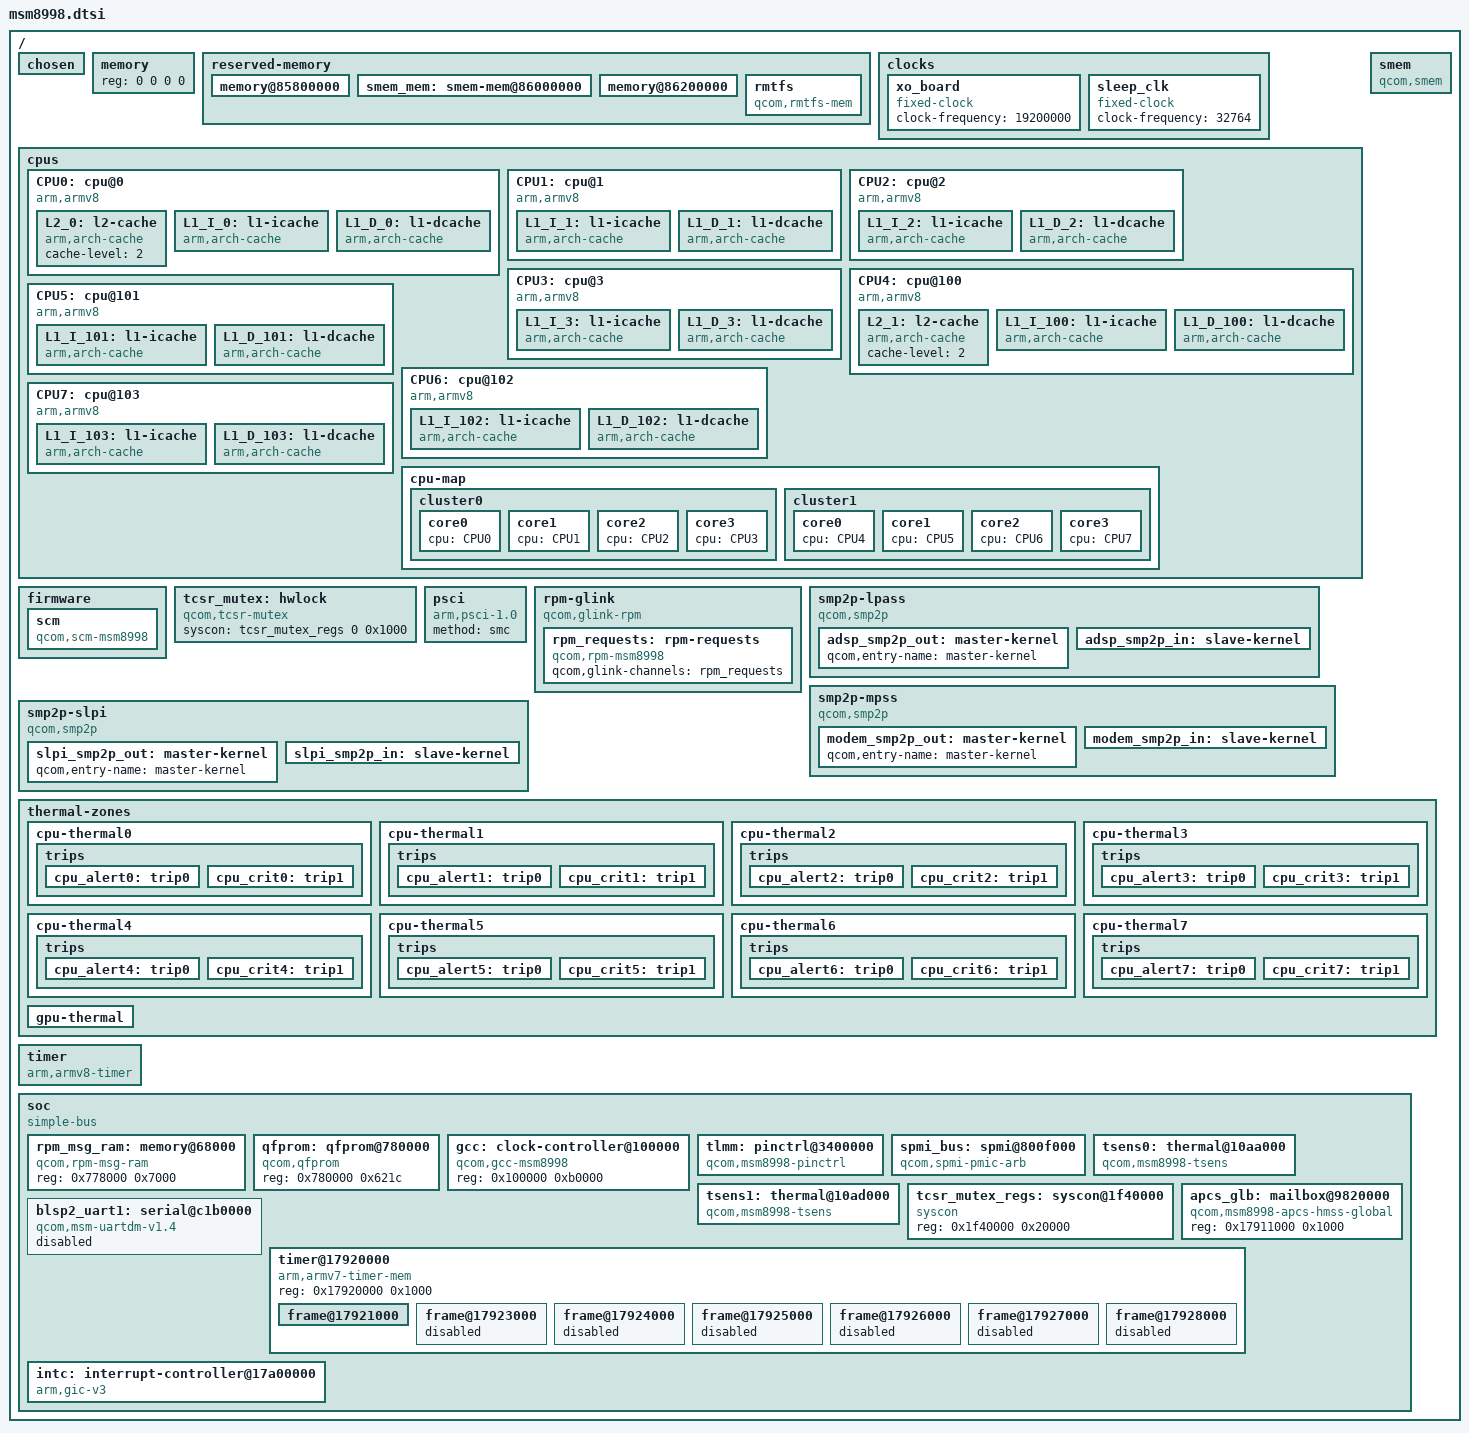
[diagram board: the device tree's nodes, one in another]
// SPDX-License-Identifier: GPL-2.0
/* Copyright (c) 2016, The Linux Foundation. All rights reserved. */

#include <dt-bindings/interrupt-controller/arm-gic.h>
#include <dt-bindings/clock/qcom,gcc-msm8998.h>

/ {
	interrupt-parent = <&intc>;

	qcom,msm-id = <292 0x0>;

	#address-cells = <2>;
	#size-cells = <2>;

	chosen { };

	memory {
		device_type = "memory";
		/* We expect the bootloader to fill in the reg */
		reg = <0 0 0 0>;
	};

	reserved-memory {
		#address-cells = <2>;
		#size-cells = <2>;
		ranges;

		memory@85800000 {
			reg = <0x0 0x85800000 0x0 0x800000>;
			no-map;
		};

		smem_mem: smem-mem@86000000 {
			reg = <0x0 0x86000000 0x0 0x200000>;
			no-map;
		};

		memory@86200000 {
			reg = <0x0 0x86200000 0x0 0x2600000>;
			no-map;
		};

		rmtfs {
			compatible = "qcom,rmtfs-mem";

			size = <0x0 0x200000>;
			alloc-ranges = <0x0 0xa0000000 0x0 0x2000000>;
			no-map;

			qcom,client-id = <1>;
			qcom,vmid = <15>;
		};
	};

	clocks {
		xo_board {
			compatible = "fixed-clock";
			#clock-cells = <0>;
			clock-frequency = <19200000>;
		};

		sleep_clk {
			compatible = "fixed-clock";
			#clock-cells = <0>;
			clock-frequency = <32764>;
		};
	};

	cpus {
		#address-cells = <2>;
		#size-cells = <0>;

		CPU0: cpu@0 {
			device_type = "cpu";
			compatible = "arm,armv8";
			reg = <0x0 0x0>;
			enable-method = "psci";
			efficiency = <1024>;
			next-level-cache = <&L2_0>;
			L2_0: l2-cache {
				compatible = "arm,arch-cache";
				cache-level = <2>;
			};
			L1_I_0: l1-icache {
				compatible = "arm,arch-cache";
			};
			L1_D_0: l1-dcache {
				compatible = "arm,arch-cache";
			};
		};

		CPU1: cpu@1 {
			device_type = "cpu";
			compatible = "arm,armv8";
			reg = <0x0 0x1>;
			enable-method = "psci";
			efficiency = <1024>;
			next-level-cache = <&L2_0>;
			L1_I_1: l1-icache {
				compatible = "arm,arch-cache";
			};
			L1_D_1: l1-dcache {
				compatible = "arm,arch-cache";
			};
		};

		CPU2: cpu@2 {
			device_type = "cpu";
			compatible = "arm,armv8";
			reg = <0x0 0x2>;
			enable-method = "psci";
			efficiency = <1024>;
			next-level-cache = <&L2_0>;
			L1_I_2: l1-icache {
				compatible = "arm,arch-cache";
			};
			L1_D_2: l1-dcache {
				compatible = "arm,arch-cache";
			};
		};

		CPU3: cpu@3 {
			device_type = "cpu";
			compatible = "arm,armv8";
			reg = <0x0 0x3>;
			enable-method = "psci";
			efficiency = <1024>;
			next-level-cache = <&L2_0>;
			L1_I_3: l1-icache {
				compatible = "arm,arch-cache";
			};
			L1_D_3: l1-dcache {
				compatible = "arm,arch-cache";
			};
		};

		CPU4: cpu@100 {
			device_type = "cpu";
			compatible = "arm,armv8";
			reg = <0x0 0x100>;
			enable-method = "psci";
			efficiency = <1536>;
			next-level-cache = <&L2_1>;
			L2_1: l2-cache {
				compatible = "arm,arch-cache";
				cache-level = <2>;
			};
			L1_I_100: l1-icache {
				compatible = "arm,arch-cache";
			};
			L1_D_100: l1-dcache {
				compatible = "arm,arch-cache";
			};
		};

		CPU5: cpu@101 {
			device_type = "cpu";
			compatible = "arm,armv8";
			reg = <0x0 0x101>;
			enable-method = "psci";
			efficiency = <1536>;
			next-level-cache = <&L2_1>;
			L1_I_101: l1-icache {
				compatible = "arm,arch-cache";
			};
			L1_D_101: l1-dcache {
				compatible = "arm,arch-cache";
			};
		};

		CPU6: cpu@102 {
			device_type = "cpu";
			compatible = "arm,armv8";
			reg = <0x0 0x102>;
			enable-method = "psci";
			efficiency = <1536>;
			next-level-cache = <&L2_1>;
			L1_I_102: l1-icache {
				compatible = "arm,arch-cache";
			};
			L1_D_102: l1-dcache {
				compatible = "arm,arch-cache";
			};
		};

		CPU7: cpu@103 {
			device_type = "cpu";
			compatible = "arm,armv8";
			reg = <0x0 0x103>;
			enable-method = "psci";
			efficiency = <1536>;
			next-level-cache = <&L2_1>;
			L1_I_103: l1-icache {
				compatible = "arm,arch-cache";
			};
			L1_D_103: l1-dcache {
				compatible = "arm,arch-cache";
			};
		};

		cpu-map {
			cluster0 {
				core0 {
					cpu = <&CPU0>;
				};

				core1 {
					cpu = <&CPU1>;
				};

				core2 {
					cpu = <&CPU2>;
				};

				core3 {
					cpu = <&CPU3>;
				};
			};

			cluster1 {
				core0 {
					cpu = <&CPU4>;
				};

				core1 {
					cpu = <&CPU5>;
				};

				core2 {
					cpu = <&CPU6>;
				};

				core3 {
					cpu = <&CPU7>;
				};
			};
		};
	};

	firmware {
		scm {
			compatible = "qcom,scm-msm8998";
		};
	};

	tcsr_mutex: hwlock {
		compatible = "qcom,tcsr-mutex";
		syscon = <&tcsr_mutex_regs 0 0x1000>;
		#hwlock-cells = <1>;
	};

	psci {
		compatible = "arm,psci-1.0";
		method = "smc";
	};

	rpm-glink {
		compatible = "qcom,glink-rpm";

		interrupts = <GIC_SPI 168 IRQ_TYPE_EDGE_RISING>;
		qcom,rpm-msg-ram = <&rpm_msg_ram>;
		mboxes = <&apcs_glb 0>;

		rpm_requests: rpm-requests {
			compatible = "qcom,rpm-msm8998";
			qcom,glink-channels = "rpm_requests";
		};
	};

	smem {
		compatible = "qcom,smem";
		memory-region = <&smem_mem>;
		hwlocks = <&tcsr_mutex 3>;
	};

	smp2p-lpass {
		compatible = "qcom,smp2p";
		qcom,smem = <443>, <429>;

		interrupts = <GIC_SPI 158 IRQ_TYPE_EDGE_RISING>;

		mboxes = <&apcs_glb 10>;

		qcom,local-pid = <0>;
		qcom,remote-pid = <2>;

		adsp_smp2p_out: master-kernel {
			qcom,entry-name = "master-kernel";
			#qcom,smem-state-cells = <1>;
		};

		adsp_smp2p_in: slave-kernel {
			qcom,entry-name = "slave-kernel";

			interrupt-controller;
			#interrupt-cells = <2>;
		};
	};

	smp2p-mpss {
		compatible = "qcom,smp2p";
		qcom,smem = <435>, <428>;
		interrupts = <GIC_SPI 451 IRQ_TYPE_EDGE_RISING>;
		mboxes = <&apcs_glb 14>;
		qcom,local-pid = <0>;
		qcom,remote-pid = <1>;

		modem_smp2p_out: master-kernel {
			qcom,entry-name = "master-kernel";
			#qcom,smem-state-cells = <1>;
		};

		modem_smp2p_in: slave-kernel {
			qcom,entry-name = "slave-kernel";
			interrupt-controller;
			#interrupt-cells = <2>;
		};
	};

	smp2p-slpi {
		compatible = "qcom,smp2p";
		qcom,smem = <481>, <430>;
		interrupts = <GIC_SPI 178 IRQ_TYPE_EDGE_RISING>;
		mboxes = <&apcs_glb 26>;
		qcom,local-pid = <0>;
		qcom,remote-pid = <3>;

		slpi_smp2p_out: master-kernel {
			qcom,entry-name = "master-kernel";
			#qcom,smem-state-cells = <1>;
		};

		slpi_smp2p_in: slave-kernel {
			qcom,entry-name = "slave-kernel";
			interrupt-controller;
			#interrupt-cells = <2>;
		};
	};

	thermal-zones {
		cpu-thermal0 {
			polling-delay-passive = <250>;
			polling-delay = <1000>;

			thermal-sensors = <&tsens0 6>;

			trips {
				cpu_alert0: trip0 {
					temperature = <75000>;
					hysteresis = <2000>;
					type = "passive";
				};

				cpu_crit0: trip1 {
					temperature = <110000>;
					hysteresis = <2000>;
					type = "critical";
				};
			};
		};

		cpu-thermal1 {
			polling-delay-passive = <250>;
			polling-delay = <1000>;

			thermal-sensors = <&tsens0 7>;

			trips {
				cpu_alert1: trip0 {
					temperature = <75000>;
					hysteresis = <2000>;
					type = "passive";
				};

				cpu_crit1: trip1 {
					temperature = <110000>;
					hysteresis = <2000>;
					type = "critical";
				};
			};
		};

		cpu-thermal2 {
			polling-delay-passive = <250>;
			polling-delay = <1000>;

			thermal-sensors = <&tsens0 8>;

			trips {
				cpu_alert2: trip0 {
					temperature = <75000>;
					hysteresis = <2000>;
					type = "passive";
				};

				cpu_crit2: trip1 {
					temperature = <110000>;
					hysteresis = <2000>;
					type = "critical";
				};
			};
		};

		cpu-thermal3 {
			polling-delay-passive = <250>;
			polling-delay = <1000>;

			thermal-sensors = <&tsens0 9>;

			trips {
				cpu_alert3: trip0 {
					temperature = <75000>;
					hysteresis = <2000>;
					type = "passive";
				};

				cpu_crit3: trip1 {
					temperature = <110000>;
					hysteresis = <2000>;
					type = "critical";
				};
			};
		};

		cpu-thermal4 {
			polling-delay-passive = <250>;
			polling-delay = <1000>;

			thermal-sensors = <&tsens0 10>;

			trips {
				cpu_alert4: trip0 {
					temperature = <75000>;
					hysteresis = <2000>;
					type = "passive";
				};

				cpu_crit4: trip1 {
					temperature = <110000>;
					hysteresis = <2000>;
					type = "critical";
				};
			};
		};

		cpu-thermal5 {
			polling-delay-passive = <250>;
			polling-delay = <1000>;

			thermal-sensors = <&tsens0 11>;

			trips {
				cpu_alert5: trip0 {
					temperature = <75000>;
					hysteresis = <2000>;
					type = "passive";
				};

				cpu_crit5: trip1 {
					temperature = <110000>;
					hysteresis = <2000>;
					type = "critical";
				};
			};
		};

		cpu-thermal6 {
			polling-delay-passive = <250>;
			polling-delay = <1000>;

			thermal-sensors = <&tsens1 0>;

			trips {
				cpu_alert6: trip0 {
					temperature = <75000>;
					hysteresis = <2000>;
					type = "passive";
				};

				cpu_crit6: trip1 {
					temperature = <110000>;
					hysteresis = <2000>;
					type = "critical";
				};
			};
		};

		cpu-thermal7 {
			polling-delay-passive = <250>;
			polling-delay = <1000>;

			thermal-sensors = <&tsens1 1>;

			trips {
				cpu_alert7: trip0 {
					temperature = <75000>;
					hysteresis = <2000>;
					type = "passive";
				};

				cpu_crit7: trip1 {
					temperature = <110000>;
					hysteresis = <2000>;
					type = "critical";
				};
			};
		};

		gpu-thermal {
			polling-delay-passive = <250>;
			polling-delay = <1000>;

			thermal-sensors = <&tsens1 3>;
		};
	};

	timer {
		compatible = "arm,armv8-timer";
		interrupts = <GIC_PPI 1 IRQ_TYPE_LEVEL_LOW>,
			     <GIC_PPI 2 IRQ_TYPE_LEVEL_LOW>,
			     <GIC_PPI 3 IRQ_TYPE_LEVEL_LOW>,
			     <GIC_PPI 0 IRQ_TYPE_LEVEL_LOW>;
	};

	soc: soc {
		#address-cells = <1>;
		#size-cells = <1>;
		ranges = <0 0 0 0xffffffff>;
		compatible = "simple-bus";

		rpm_msg_ram: memory@68000 {
			compatible = "qcom,rpm-msg-ram";
			reg = <0x778000 0x7000>;
		};

		qfprom: qfprom@780000 {
			compatible = "qcom,qfprom";
			reg = <0x780000 0x621c>;
			#address-cells = <1>;
			#size-cells = <1>;
		};

		gcc: clock-controller@100000 {
			compatible = "qcom,gcc-msm8998";
			#clock-cells = <1>;
			#reset-cells = <1>;
			#power-domain-cells = <1>;
			reg = <0x100000 0xb0000>;
		};

		tlmm: pinctrl@3400000 {
			compatible = "qcom,msm8998-pinctrl";
			reg = <0x3400000 0xc00000>;
			interrupts = <GIC_SPI 208 IRQ_TYPE_LEVEL_HIGH>;
			gpio-controller;
			#gpio-cells = <0x2>;
			interrupt-controller;
			#interrupt-cells = <0x2>;
		};

		spmi_bus: spmi@800f000 {
			compatible = "qcom,spmi-pmic-arb";
			reg =	<0x800f000 0x1000>,
				<0x8400000 0x1000000>,
				<0x9400000 0x1000000>,
				<0xa400000 0x220000>,
				<0x800a000 0x3000>;
			reg-names = "core", "chnls", "obsrvr", "intr", "cnfg";
			interrupt-names = "periph_irq";
			interrupts = <GIC_SPI 326 IRQ_TYPE_LEVEL_HIGH>;
			qcom,ee = <0>;
			qcom,channel = <0>;
			#address-cells = <2>;
			#size-cells = <0>;
			interrupt-controller;
			#interrupt-cells = <4>;
			cell-index = <0>;
		};

		tsens0: thermal@10aa000 {
			compatible = "qcom,msm8998-tsens", "qcom,tsens-v2";
			reg = <0x10aa000 0x2000>;

			#qcom,sensors = <12>;
			#thermal-sensor-cells = <1>;
		};

		tsens1: thermal@10ad000 {
			compatible = "qcom,msm8998-tsens", "qcom,tsens-v2";
			reg = <0x10ad000 0x2000>;

			#qcom,sensors = <8>;
			#thermal-sensor-cells = <1>;
		};

		tcsr_mutex_regs: syscon@1f40000 {
			compatible = "syscon";
			reg = <0x1f40000 0x20000>;
		};

		apcs_glb: mailbox@9820000 {
			compatible = "qcom,msm8998-apcs-hmss-global";
			reg = <0x17911000 0x1000>;

			#mbox-cells = <1>;
		};

		blsp2_uart1: serial@c1b0000 {
			compatible = "qcom,msm-uartdm-v1.4", "qcom,msm-uartdm";
			reg = <0xc1b0000 0x1000>;
			interrupts = <GIC_SPI 114 IRQ_TYPE_LEVEL_HIGH>;
			clocks = <&gcc GCC_BLSP2_UART2_APPS_CLK>,
				 <&gcc GCC_BLSP2_AHB_CLK>;
			clock-names = "core", "iface";
			status = "disabled";
		};

		timer@17920000 {
			#address-cells = <1>;
			#size-cells = <1>;
			ranges;
			compatible = "arm,armv7-timer-mem";
			reg = <0x17920000 0x1000>;

			frame@17921000 {
				frame-number = <0>;
				interrupts = <GIC_SPI 8 IRQ_TYPE_LEVEL_HIGH>,
					     <GIC_SPI 7 IRQ_TYPE_LEVEL_HIGH>;
				reg = <0x17921000 0x1000>,
				      <0x17922000 0x1000>;
			};

			frame@17923000 {
				frame-number = <1>;
				interrupts = <GIC_SPI 9 IRQ_TYPE_LEVEL_HIGH>;
				reg = <0x17923000 0x1000>;
				status = "disabled";
			};

			frame@17924000 {
				frame-number = <2>;
				interrupts = <GIC_SPI 10 IRQ_TYPE_LEVEL_HIGH>;
				reg = <0x17924000 0x1000>;
				status = "disabled";
			};

			frame@17925000 {
				frame-number = <3>;
				interrupts = <GIC_SPI 11 IRQ_TYPE_LEVEL_HIGH>;
				reg = <0x17925000 0x1000>;
				status = "disabled";
			};

			frame@17926000 {
				frame-number = <4>;
				interrupts = <GIC_SPI 12 IRQ_TYPE_LEVEL_HIGH>;
				reg = <0x17926000 0x1000>;
				status = "disabled";
			};

			frame@17927000 {
				frame-number = <5>;
				interrupts = <GIC_SPI 13 IRQ_TYPE_LEVEL_HIGH>;
				reg = <0x17927000 0x1000>;
				status = "disabled";
			};

			frame@17928000 {
				frame-number = <6>;
				interrupts = <GIC_SPI 14 IRQ_TYPE_LEVEL_HIGH>;
				reg = <0x17928000 0x1000>;
				status = "disabled";
			};
		};

		intc: interrupt-controller@17a00000 {
			compatible = "arm,gic-v3";
			reg = <0x17a00000 0x10000>,       /* GICD */
			      <0x17b00000 0x100000>;      /* GICR * 8 */
			#interrupt-cells = <3>;
			#address-cells = <1>;
			#size-cells = <1>;
			ranges;
			interrupt-controller;
			#redistributor-regions = <1>;
			redistributor-stride = <0x0 0x20000>;
			interrupts = <GIC_PPI 9 IRQ_TYPE_LEVEL_HIGH>;
		};
	};
};
